# ATtiny167 register map
Vendor: Atmel; File version: 1.0
CPU: other r0p0, little endian, no MPU, no FPU, 4 interrupt priority bits
Registers are 8-bit, read-write, reset 0x0 unless marked. A register's access mark holds for its fields unless they carry their own. Offsets are from the block's base; lines under a group give offsets from that group; [hi:lo] are bit positions; {n}, {i} and the like mark numbered series; 'fields as' and 'values as' point back to an identical list; <NAME> marks a mode.

## Memory map
0x00000000 FUSE size 0x3 — Fuses
0x00000000 LOCKBIT size 0x1 — Lockbits
0x00000020 PORTA size 0x3 — I/O Port
0x00000023 PORTB size 0x3 — I/O Port
0x00000032 CPU blocks up to offset 0x35 — CPU Registers
0x00000035 TC0 blocks up to offset 0x82 — Timer/Counter, 8-bit Async
0x00000036 TC1 blocks up to offset 0x56 — Timer/Counter, 16-bit
0x0000003B EXINT blocks up to offset 0x32 — External Interrupts
0x0000003F EEPROM size 0x4
0x0000004C SPI size 0x3 — Serial Peripheral Interface
0x00000050 AC blocks up to offset 0x2C — Analog Comparator
0x00000057 BOOT_LOAD size 0x1 — Bootloader
0x00000060 WDT size 0x1 — Watchdog Timer
0x00000077 ADC blocks up to offset 0x9 — Analog-to-Digital Converter
0x00000077 CURRENT_SOURCE size 0x1
0x000000B8 USI size 0x5 — Universal Serial Interface
0x000000C8 LINUART size 0xB — Local Interconnect Network

## Interrupts
0 RESET (CPU) — External Reset, Power-on Reset and Watchdog Reset
1 INT0 (CPU) — External Interrupt Request 0
2 INT1 (CPU) — External Interrupt Request 1
3 PCINT0 (CPU) — Pin Change Interrupt Request 0
4 PCINT1 (CPU) — Pin Change Interrupt Request 1
5 WDT (CPU) — Watchdog Time-Out Interrupt
6 TIMER1_CAPT (CPU) — Timer/Counter1 Capture Event
7 TIMER1_COMPA (CPU) — Timer/Counter1 Compare Match 1A
8 TIMER1_COMPB (CPU) — Timer/Counter1 Compare Match 1B
9 TIMER1_OVF (CPU) — Timer/Counter1 Overflow
10 TIMER0_COMPA (CPU) — Timer/Counter0 Compare Match 0A
11 TIMER0_OVF (CPU) — Timer/Counter0 Overflow
12 LIN_TC (CPU) — LIN Transfer Complete
13 LIN_ERR (CPU) — LIN Error
14 SPI_STC (CPU) — SPI Serial Transfer Complete
15 ADC (CPU) — ADC Conversion Complete
16 EE_RDY (CPU) — EEPROM Ready
17 ANA_COMP (CPU) — Analog Comparator
18 USI_START (CPU) — USI Start Condition Detection
19 USI_OVF (CPU) — USI Counter Overflow

## AC — Analog Comparator
Base 0x00000050
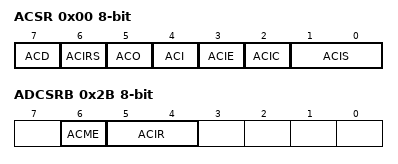
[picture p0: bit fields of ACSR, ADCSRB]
0x00 ACSR — Analog Comparator Control And Status Register
  [7] ACD — Analog Comparator Disable
  [6] ACIRS — Analog Comparator Internal Reference Select
  [5] ACO — Analog Compare Output
  [4] ACI — Analog Comparator Interrupt Flag
  [3] ACIE — Analog Comparator Interrupt Enable
  [2] ACIC — Analog Comparator Input Capture Enable
  [1:0] ACIS — Analog Comparator Interrupt Mode Select bits
    0=Interrupt on Toggle; 2=Interrupt on Falling Edge; 3=Interrupt on Rising Edge
0x2B ADCSRB — Analog Comparator & ADC Control and Status Register B (Shared with AD_CONVERTER IO_MODULE)
  [6] ACME — Analog Comparator Multiplexer Enable
  [5:4] ACIR — Analog Comparator Internal Voltage Reference Select Bits

## ADC — Analog-to-Digital Converter
Base 0x00000077
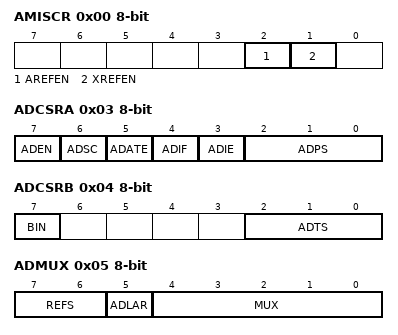
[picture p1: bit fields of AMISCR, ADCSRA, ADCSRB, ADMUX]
0x00 AMISCR — Analog Miscellaneous Control Register (Shared with CURRENT_SOURCE IO_MODULE)
  [2] AREFEN — External Voltage Reference Input Enable
  [1] XREFEN — Internal Voltage Reference Output Enable
0x01 ADC 16-bit (reset mask 0xFF) — ADC Data Register Bytes
0x03 ADCSRA — The ADC Control and Status register A
  [7] ADEN — ADC Enable
  [6] ADSC — ADC Start Conversion
  [5] ADATE — ADC Auto Trigger Enable
  [4] ADIF — ADC Interrupt Flag
  [3] ADIE — ADC Interrupt Enable
  [2:0] ADPS — ADC Prescaler Select Bits
    0=2; 1=2; 2=4; 3=8; 4=16; 5=32; 6=64; 7=128
0x04 ADCSRB — The ADC Control and Status register B (Shared with ANALOG_COMPARATOR IO_MODULE)
  [7] BIN — Bipolar Input Mode
  [2:0] ADTS — ADC Auto Trigger Source bits
    0=Free Running mode; 1=Analog Comparator; 2=External Interrupt Request 0; 3=Timer/Counter1 Compare Match A; 4=Timer/Counter1 Overflow; 5=Timer/Counter1 Compare Match B; 6=Timer/Counter1 Capture Event; 7=Watchdog Interrupt Request
0x05 ADMUX — The ADC multiplexer Selection Register
  [7:6] REFS — Reference Selection Bits
    0=If AREFEN==0 then Internal AVCC as Voltage Reference. If AREFEN==1 then AREF pin as Voltage Reference.; 1=If AREFEN==0 then Internal 1.1V as Voltage Reference without external capacitor. If AREFEN==1 then Internal 1.1V as Voltage Reference with external capacitor at AREF pin.; 2=If AREFEN==0 then Internal AVCC as Voltage Reference. If AREFEN==1 then AREF pin as Voltage Reference.; 3=If AREFEN==0 then Internal 2.56V as Voltage Reference without external capacitor. If AREFEN==1 then Internal 2.56V as Voltage Reference with external capacitor at AREF pin.
  [5] ADLAR — Left Adjust Result
  [4:0] MUX — Analog Channel and Gain Selection Bits
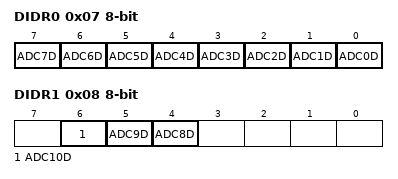
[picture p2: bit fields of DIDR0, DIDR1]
0x07 DIDR0 — Digital Input Disable Register 0
  [n] ADC{n}D (n=0..7)
0x08 DIDR1 — Digital Input Disable Register 1
  [6] ADC10D, [5] ADC9D, [4] ADC8D
